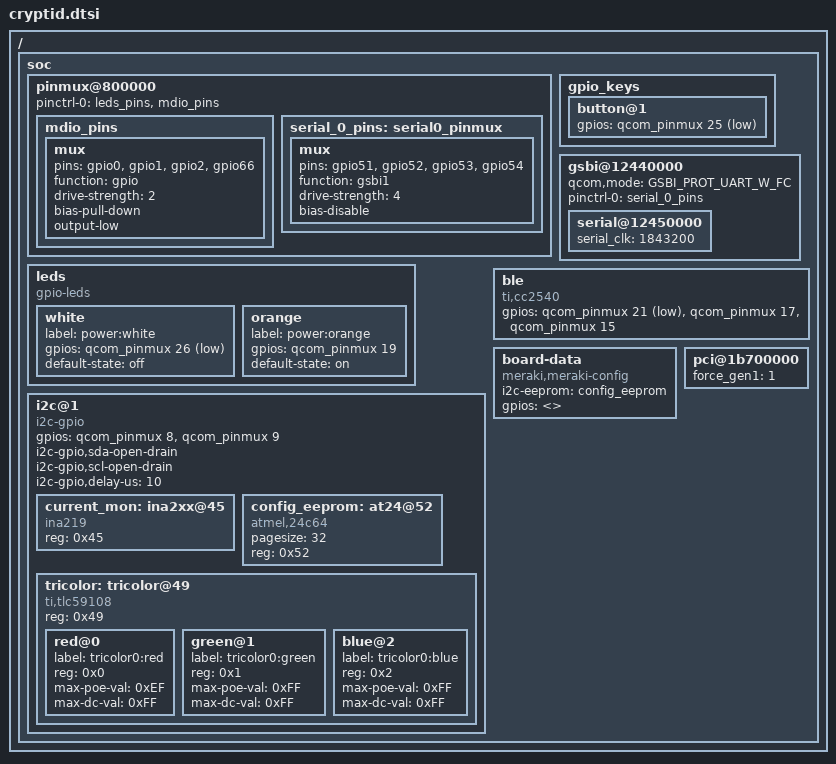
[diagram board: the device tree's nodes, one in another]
/* Copyright (c) 2015, The Linux Foundation. All rights reserved.
 *
 * Permission to use, copy, modify, and/or distribute this software for any
 * purpose with or without fee is hereby granted, provided that the above
 * copyright notice and this permission notice appear in all copies.
 *
 * THE SOFTWARE IS PROVIDED "AS IS" AND THE AUTHOR DISCLAIMS ALL WARRANTIES
 * WITH REGARD TO THIS SOFTWARE INCLUDING ALL IMPLIED WARRANTIES OF
 * MERCHANTABILITY AND FITNESS. IN NO EVENT SHALL THE AUTHOR BE LIABLE FOR
 * ANY SPECIAL, DIRECT, INDIRECT, OR CONSEQUENTIAL DAMAGES OR ANY DAMAGES
 * WHATSOEVER RESULTING FROM LOSS OF USE, DATA OR PROFITS, WHETHER IN AN
 * ACTION OF CONTRACT, NEGLIGENCE OR OTHER TORTIOUS ACTION, ARISING OUT OF
 * OR IN CONNECTION WITH THE USE OR PERFORMANCE OF THIS SOFTWARE.
 *
 */

/ {
	soc {

		pinmux@800000 {
			pinctrl-0 = <&leds_pins &mdio_pins>;
			mdio_pins: mdio_pins {
				mux {
					pins = "gpio0", "gpio1", "gpio2", "gpio66";
					function = "gpio";
					drive-strength = <2>;
					bias-pull-down;
					output-low;
				};
			};

			serial_0_pins: serial0_pinmux {
				mux {
					pins = "gpio51", "gpio52", "gpio53", "gpio54";
					function = "gsbi1";
                                        drive-strength = <4>;
					bias-disable;
				};
			};
		};

		leds {
			compatible = "gpio-leds";

			white {
				label = "power:white";
				gpios = <&qcom_pinmux 26 1>;
				default-state = "off";
			};

			orange {
				label = "power:orange";
				gpios = <&qcom_pinmux 19 0>;
				default-state = "on";
			};
		};

		gpio_keys {
			button@1 {
				gpios = <&qcom_pinmux 25 1>;
			};
		};

		i2c@1 {
			compatible = "i2c-gpio";
			gpios = <&qcom_pinmux 8 0>, <&qcom_pinmux 9 0>;
			i2c-gpio,sda-open-drain;
			i2c-gpio,scl-open-drain;
			i2c-gpio,delay-us = <10>;
			#address-cells = <1>;
			#size-cells = <0>;

			current_mon: ina2xx@45 {
				compatible = "ina219";
				reg = <0x45>;
			};

			config_eeprom: at24@52 {
				compatible = "atmel,24c64";
				pagesize = <32>;
				reg = <0x52>;
			};

			tricolor: tricolor@49 {
				#address-cells = <1>;
				#size-cells = <0>;
				compatible = "ti,tlc59108";
				reg = <0x49>;

				red@0 {
					label = "tricolor0:red";
					reg = <0x0>;
					max-poe-val = <0xEF>;
					max-dc-val  = <0xFF>;
				};

				green@1 {
					label = "tricolor0:green";
					reg = <0x1>;
					max-poe-val = <0xFF>;
					max-dc-val  = <0xFF>;
				};

				blue@2 {
					label = "tricolor0:blue";
					reg = <0x2>;
					max-poe-val = <0xFF>;
					max-dc-val  = <0xFF>;
				};
			};
		};

		gsbi@12440000 {
			qcom,mode = <GSBI_PROT_UART_W_FC>;
			pinctrl-0 = <&serial_0_pins>;
			pinctrl-names = "default";
			status = "ok";
			serial@12450000 {
				status = "ok";
                                serial_clk = <1843200>;
			};
		};

		ble {
			compatible = "ti,cc2540";
			gpios = <&qcom_pinmux 21 1>, //reset
				<&qcom_pinmux 17 0>, //clk
				<&qcom_pinmux 15 0>; //data
		};

		board-data {
			compatible = "meraki,meraki-config";
			i2c-eeprom = <&config_eeprom>;
			gpios = <>;
		};

		pci@1b700000 {
			force_gen1 = <1>;
		};
	};
};
